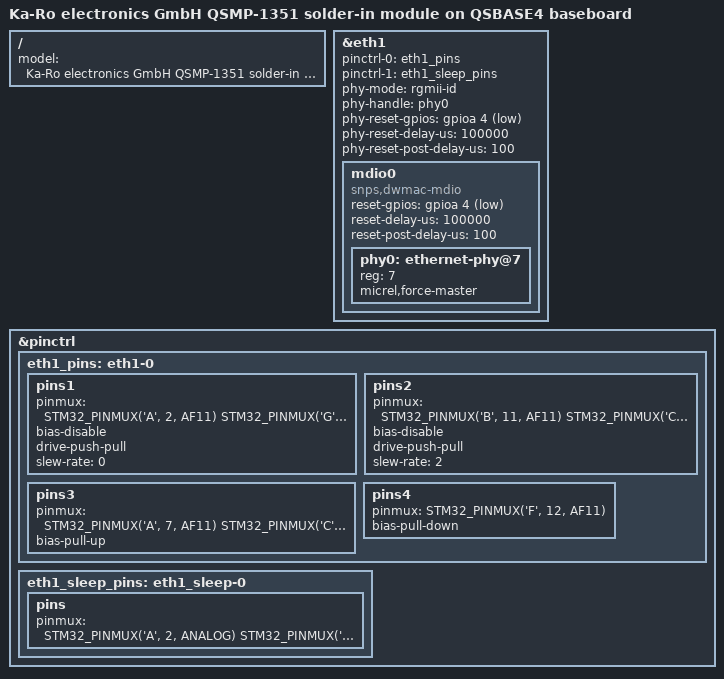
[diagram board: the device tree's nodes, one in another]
// SPDX-License-Identifier: (GPL-2.0-only OR BSD-3-Clause)
/*
 * Based on STM32CubeMX tool generated source.
 *
 * Copyright (C) 2024 Markus Bauer <MB@KARO-electronics.de>
 */

/dts-v1/;

#include "stm32mp135c-qsmp-1351.dts"
#include <dt-bindings/gpio/gpio.h>

/ {
	model = "Ka-Ro electronics GmbH QSMP-1351 solder-in module on QSBASE4 baseboard";
};

&eth1 {
	pinctrl-names = "default", "sleep";
	pinctrl-0 = <&eth1_pins>;
	pinctrl-1 = <&eth1_sleep_pins>;
	phy-mode = "rgmii-id";
	phy-handle = <&phy0>;
	phy-reset-gpios = <&gpioa 4 GPIO_ACTIVE_LOW>;
	phy-reset-delay-us = <100000>;
	phy-reset-post-delay-us = <100>;
	status = "okay";

	mdio0: mdio0 {
		#address-cells = <1>;
		#size-cells = <0>;
		compatible = "snps,dwmac-mdio";
		reset-gpios = <&gpioa 4 GPIO_ACTIVE_LOW>;
		reset-delay-us = <100000>;
		reset-post-delay-us = <100>;

		phy0: ethernet-phy@7 {
			reg = <7>;
			micrel,force-master;
		};
	};
};

&pinctrl {
	eth1_pins: eth1-0 {
		pins1 {
			pinmux = <
				  STM32_PINMUX('A', 2, AF11)	/* ETH1_MDIO */
				  STM32_PINMUX('G', 2, AF11)	/* ETH1_MDC */
			>;
			bias-disable;
			drive-push-pull;
			slew-rate = <0>;
		};

		pins2 {
			pinmux = <
				  STM32_PINMUX('B', 11, AF11)	/* ETH1_TX_CTL */
				  STM32_PINMUX('C', 1, AF11)	/* ETH1_GTX_CLK */
				  STM32_PINMUX('G', 13, AF11)	/* ETH1_TXD0 */
				  STM32_PINMUX('G', 14, AF11)	/* ETH1_TXD1 */
				  STM32_PINMUX('C', 2, AF11)	/* ETH1_TXD2 */
				  STM32_PINMUX('E', 5, AF10)	/* ETH1_TXD3 */
			>;
			bias-disable;
			drive-push-pull;
			slew-rate = <2>;
		};

		pins3 {
			pinmux = <
				  STM32_PINMUX('A', 7, AF11)	/* RX_CTL | CLK125_EN */
				  STM32_PINMUX('C', 4, AF11)	/* RXD0 | MODE0 */
				  STM32_PINMUX('C', 5, AF11)	/* RXD1 | MODE1 */
				  STM32_PINMUX('B', 0, AF11)	/* RXD2 | MODE2 */
				  STM32_PINMUX('B', 1, AF11)	/* RXD3 | MODE3 */
				  STM32_PINMUX('D', 7, AF10)	/* ETH1_RX_CLK | PHAYD2 */
			>;
			bias-pull-up;
		};

		pins4 {
			pinmux = <
				  STM32_PINMUX('F', 12, AF11)	/* ETH1_CLK125 | LED_MODE */
			>;
			bias-pull-down;
		};
	};

	eth1_sleep_pins: eth1_sleep-0 {
		pins {
			pinmux = <
				  STM32_PINMUX('A', 2, ANALOG)	 /* ETH1_MDIO */
				  STM32_PINMUX('A', 7, ANALOG)	 /* ETH1_RX_CTL */
				  STM32_PINMUX('B', 0, ANALOG)	 /* ETH1_RXD2 */
				  STM32_PINMUX('B', 1, ANALOG)	 /* ETH1_RXD3 */
				  STM32_PINMUX('B', 11, ANALOG)	 /* ETH1_TX_CTL */
				  STM32_PINMUX('C', 1, ANALOG)	 /* ETH1_GTX_CLK */
				  STM32_PINMUX('C', 2, ANALOG)	 /* ETH1_TXD2 */
				  STM32_PINMUX('C', 4, ANALOG)	 /* ETH1_RXD0 */
				  STM32_PINMUX('C', 5, ANALOG)	 /* ETH1_RXD1 */
				  STM32_PINMUX('D', 7, ANALOG)	 /* ETH1_RX_CLK */
				  STM32_PINMUX('E', 5, ANALOG)	 /* ETH1_TXD3 */
				  STM32_PINMUX('F', 12, ANALOG)	 /* ETH1_CLK125 */
				  STM32_PINMUX('G', 2, ANALOG)	 /* ETH1_MDC */
				  STM32_PINMUX('G', 13, ANALOG)	 /* ETH1_TXD0 */
				  STM32_PINMUX('G', 14, ANALOG)	 /* ETH1_TXD1 */
				  STM32_PINMUX('H', 6, ANALOG)	 /* ETH1_PHY_INTN */
			>;
		};
	};
};
